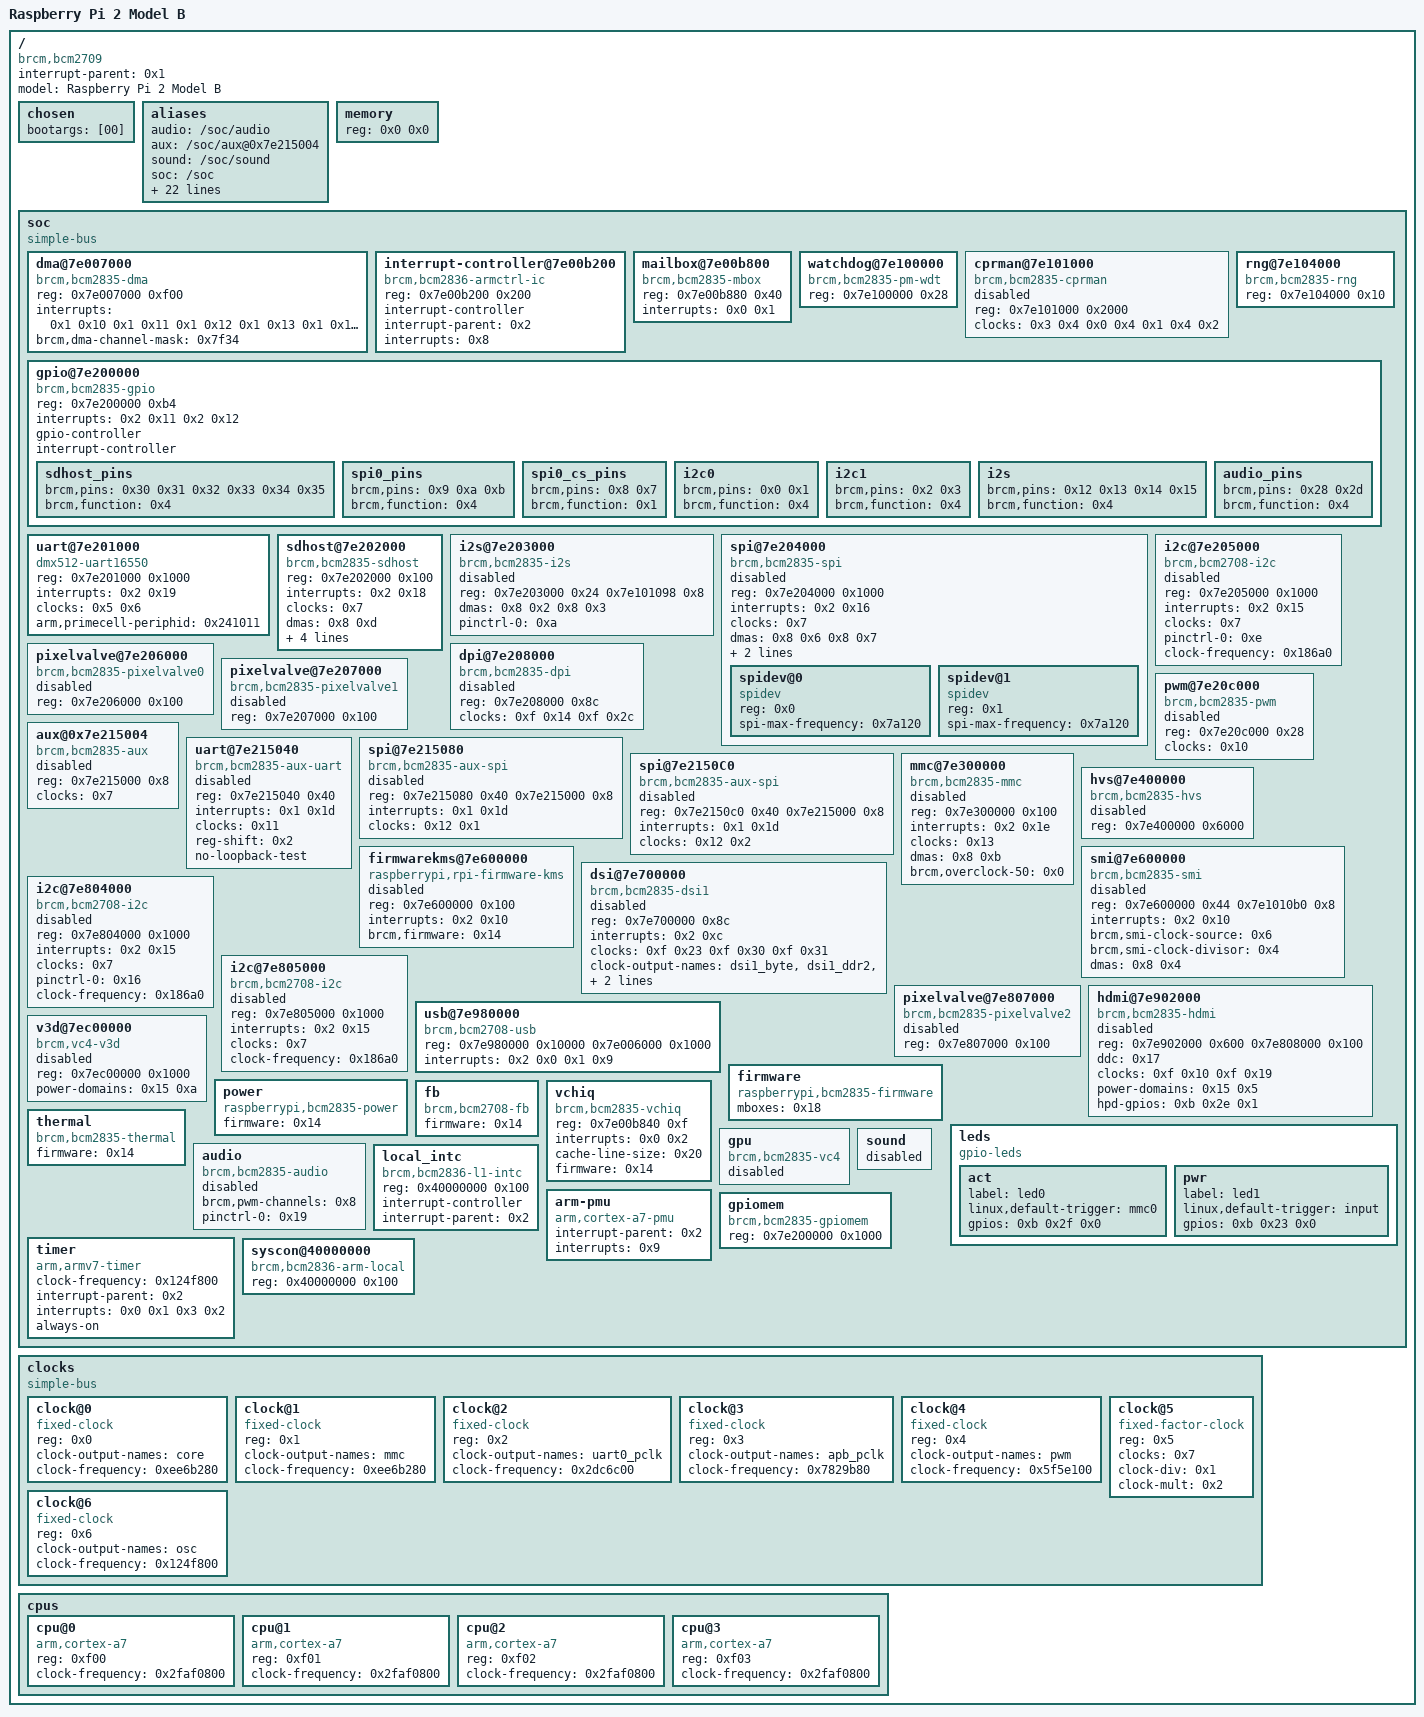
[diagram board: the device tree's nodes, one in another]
/dts-v1/;

/ {
	#address-cells = <0x1>;
	#size-cells = <0x1>;
	interrupt-parent = <0x1>;
	compatible = "brcm,bcm2709";
	model = "Raspberry Pi 2 Model B";

	chosen {
		bootargs = [00];
	};

	aliases {
		audio = "/soc/audio";
		aux = "/soc/aux@0x7e215004";
		sound = "/soc/sound";
		soc = "/soc";
		dma = "/soc/dma@7e007000";
		intc = "/soc/interrupt-controller@7e00b200";
		watchdog = "/soc/watchdog@7e100000";
		random = "/soc/rng@7e104000";
		mailbox = "/soc/mailbox@7e00b800";
		gpio = "/soc/gpio@7e200000";
		/*uart0 = "/soc/uart@7e201000"; */
		sdhost = "/soc/sdhost@7e202000";
		i2s = "/soc/i2s@7e203000";
		spi0 = "/soc/spi@7e204000";
		i2c0 = "/soc/i2c@7e205000";
		uart1 = "/soc/uart@7e215040";
		spi1 = "/soc/spi@7e215080";
		spi2 = "/soc/spi@7e2150C0";
		mmc = "/soc/mmc@7e300000";
		i2c1 = "/soc/i2c@7e804000";
		i2c2 = "/soc/i2c@7e805000";
		usb = "/soc/usb@7e980000";
		leds = "/soc/leds";
		fb = "/soc/fb";
		vchiq = "/soc/vchiq";
		thermal = "/soc/thermal";
		clocks = "/clocks";
	};

	memory {
		device_type = "memory";
		reg = <0x0 0x0>;
	};

	soc {
		compatible = "simple-bus";
		#address-cells = <0x1>;
		#size-cells = <0x1>;
		ranges = <0x7e000000 0x3f000000 0x1000000 0x40000000 0x40000000 0x40000>;
		phandle = <0x2b>;

		dma@7e007000 {
			compatible = "brcm,bcm2835-dma";
			reg = <0x7e007000 0xf00>;
			interrupts = <0x1 0x10 0x1 0x11 0x1 0x12 0x1 0x13 0x1 0x14 0x1 0x15 0x1 0x16 0x1 0x17 0x1 0x18 0x1 0x19 0x1 0x1a 0x1 0x1b 0x1 0x1b 0x1 0x1b 0x1 0x1b 0x1 0x1c>;
			interrupt-names = "dma0", "dma1", "dma2", "dma3", "dma4", "dma5", "dma6", "dma7", "dma8", "dma9", "dma10", "dma11", "dma12", "dma13", "dma14", "dma-shared-all";
			#dma-cells = <0x1>;
			brcm,dma-channel-mask = <0x7f34>;
			phandle = <0x8>;
		};

		interrupt-controller@7e00b200 {
			compatible = "brcm,bcm2836-armctrl-ic";
			reg = <0x7e00b200 0x200>;
			interrupt-controller;
			#interrupt-cells = <0x2>;
			interrupt-parent = <0x2>;
			interrupts = <0x8>;
			phandle = <0x1>;
		};

		mailbox@7e00b800 {
			compatible = "brcm,bcm2835-mbox";
			reg = <0x7e00b880 0x40>;
			interrupts = <0x0 0x1>;
			#mbox-cells = <0x0>;
			phandle = <0x18>;
		};

		watchdog@7e100000 {
			compatible = "brcm,bcm2835-pm-wdt";
			reg = <0x7e100000 0x28>;
			status = "okay";
			phandle = <0x28>;
		};

		cprman@7e101000 {
			compatible = "brcm,bcm2835-cprman";
			#clock-cells = <0x1>;
			reg = <0x7e101000 0x2000>;
			clocks = <0x3 0x4 0x0 0x4 0x1 0x4 0x2>;
			status = "disabled";
			phandle = <0xf>;
		};

		rng@7e104000 {
			compatible = "brcm,bcm2835-rng";
			reg = <0x7e104000 0x10>;
			status = "okay";
			phandle = <0x29>;
		};

		gpio@7e200000 {
			compatible = "brcm,bcm2835-gpio";
			reg = <0x7e200000 0xb4>;
			interrupts = <0x2 0x11 0x2 0x12>;
			gpio-controller;
			#gpio-cells = <0x2>;
			interrupt-controller;
			#interrupt-cells = <0x2>;
			phandle = <0xb>;

			sdhost_pins {
				brcm,pins = <0x30 0x31 0x32 0x33 0x34 0x35>;
				brcm,function = <0x4>;
				phandle = <0x9>;
			};

			spi0_pins {
				brcm,pins = <0x9 0xa 0xb>;
				brcm,function = <0x4>;
				phandle = <0xc>;
			};

			spi0_cs_pins {
				brcm,pins = <0x8 0x7>;
				brcm,function = <0x1>;
				phandle = <0xd>;
			};

			i2c0 {
				brcm,pins = <0x0 0x1>;
				brcm,function = <0x4>;
				phandle = <0xe>;
			};

			i2c1 {
				brcm,pins = <0x2 0x3>;
				brcm,function = <0x4>;
				phandle = <0x16>;
			};

			i2s {
				brcm,pins = <0x12 0x13 0x14 0x15>;
				brcm,function = <0x4>;
				phandle = <0xa>;
			};

			audio_pins {
				brcm,pins = <0x28 0x2d>;
				brcm,function = <0x4>;
				phandle = <0x19>;
			};
		};

		uart@7e201000 {
			compatible = "dmx512-uart16550";
			reg = <0x7e201000 0x1000>;
			interrupts = <0x2 0x19>;
			clocks = <0x5 0x6>;
			clock-names = "uartclk", "apb_pclk";
			arm,primecell-periphid = <0x241011>;
			status = "okay";
			phandle = <0x1f>;
		};
/*
		uart@7e201000 {
			compatible = "arm,pl011", "arm,primecell";
			reg = <0x7e201000 0x1000>;
			interrupts = <0x2 0x19>;
			clocks = <0x5 0x6>;
			clock-names = "uartclk", "apb_pclk";
			arm,primecell-periphid = <0x241011>;
			status = "okay";
			phandle = <0x1f>;
		};
*/

		sdhost@7e202000 {
			compatible = "brcm,bcm2835-sdhost";
			reg = <0x7e202000 0x100>;
			interrupts = <0x2 0x18>;
			clocks = <0x7>;
			dmas = <0x8 0xd>;
			dma-names = "rx-tx";
			brcm,overclock-50 = <0x0>;
			brcm,pio-limit = <0x1>;
			status = "okay";
			pinctrl-names = "default";
			pinctrl-0 = <0x9>;
			bus-width = <0x4>;
			phandle = <0x2a>;
		};

		i2s@7e203000 {
			compatible = "brcm,bcm2835-i2s";
			#sound-dai-cells = <0x0>;
			reg = <0x7e203000 0x24 0x7e101098 0x8>;
			dmas = <0x8 0x2 0x8 0x3>;
			dma-names = "tx", "rx";
			status = "disabled";
			pinctrl-names = "default";
			pinctrl-0 = <0xa>;
			phandle = <0x21>;
		};

		spi@7e204000 {
			compatible = "brcm,bcm2835-spi";
			reg = <0x7e204000 0x1000>;
			interrupts = <0x2 0x16>;
			clocks = <0x7>;
			#address-cells = <0x1>;
			#size-cells = <0x0>;
			status = "disabled";
			dmas = <0x8 0x6 0x8 0x7>;
			dma-names = "tx", "rx";
			cs-gpios = <0xb 0x8 0x1 0xb 0x7 0x1>;
			pinctrl-names = "default";
			pinctrl-0 = <0xc 0xd>;
			phandle = <0x22>;

			spidev@0 {
				compatible = "spidev";
				reg = <0x0>;
				#address-cells = <0x1>;
				#size-cells = <0x0>;
				spi-max-frequency = <0x7a120>;
				phandle = <0x2c>;
			};

			spidev@1 {
				compatible = "spidev";
				reg = <0x1>;
				#address-cells = <0x1>;
				#size-cells = <0x0>;
				spi-max-frequency = <0x7a120>;
				phandle = <0x2d>;
			};
		};

		i2c@7e205000 {
			compatible = "brcm,bcm2708-i2c";
			reg = <0x7e205000 0x1000>;
			interrupts = <0x2 0x15>;
			clocks = <0x7>;
			#address-cells = <0x1>;
			#size-cells = <0x0>;
			status = "disabled";
			pinctrl-names = "default";
			pinctrl-0 = <0xe>;
			clock-frequency = <0x186a0>;
			phandle = <0x23>;
		};

		pixelvalve@7e206000 {
			compatible = "brcm,bcm2835-pixelvalve0";
			reg = <0x7e206000 0x100>;
			status = "disabled";
			phandle = <0x2e>;
		};

		dpi@7e208000 {
			compatible = "brcm,bcm2835-dpi";
			reg = <0x7e208000 0x8c>;
			clocks = <0xf 0x14 0xf 0x2c>;
			clock-names = "core", "pixel";
			#address-cells = <0x1>;
			#size-cells = <0x0>;
			status = "disabled";
			phandle = <0x2f>;
		};

		pixelvalve@7e207000 {
			compatible = "brcm,bcm2835-pixelvalve1";
			reg = <0x7e207000 0x100>;
			status = "disabled";
			phandle = <0x30>;
		};

		pwm@7e20c000 {
			compatible = "brcm,bcm2835-pwm";
			reg = <0x7e20c000 0x28>;
			clocks = <0x10>;
			#pwm-cells = <0x2>;
			status = "disabled";
			phandle = <0x31>;
		};

		aux@0x7e215004 {
			compatible = "brcm,bcm2835-aux";
			#clock-cells = <0x1>;
			reg = <0x7e215000 0x8>;
			clocks = <0x7>;
			status = "disabled";
			phandle = <0x12>;
		};

		uart@7e215040 {
			compatible = "brcm,bcm2835-aux-uart", "ns16550";
			reg = <0x7e215040 0x40>;
			interrupts = <0x1 0x1d>;
			clocks = <0x11>;
			reg-shift = <0x2>;
			no-loopback-test;
			status = "disabled";
			phandle = <0x20>;
		};

		spi@7e215080 {
			compatible = "brcm,bcm2835-aux-spi";
			reg = <0x7e215080 0x40 0x7e215000 0x8>;
			interrupts = <0x1 0x1d>;
			clocks = <0x12 0x1>;
			#address-cells = <0x1>;
			#size-cells = <0x0>;
			status = "disabled";
			phandle = <0x32>;
		};

		spi@7e2150C0 {
			compatible = "brcm,bcm2835-aux-spi";
			reg = <0x7e2150c0 0x40 0x7e215000 0x8>;
			interrupts = <0x1 0x1d>;
			clocks = <0x12 0x2>;
			#address-cells = <0x1>;
			#size-cells = <0x0>;
			status = "disabled";
			phandle = <0x33>;
		};

		mmc@7e300000 {
			compatible = "brcm,bcm2835-mmc";
			reg = <0x7e300000 0x100>;
			interrupts = <0x2 0x1e>;
			clocks = <0x13>;
			dmas = <0x8 0xb>;
			dma-names = "rx-tx";
			brcm,overclock-50 = <0x0>;
			status = "disabled";
			phandle = <0x34>;
		};

		hvs@7e400000 {
			compatible = "brcm,bcm2835-hvs";
			reg = <0x7e400000 0x6000>;
			status = "disabled";
			phandle = <0x35>;
		};

		firmwarekms@7e600000 {
			compatible = "raspberrypi,rpi-firmware-kms";
			reg = <0x7e600000 0x100>;
			interrupts = <0x2 0x10>;
			brcm,firmware = <0x14>;
			status = "disabled";
			phandle = <0x36>;
		};

		smi@7e600000 {
			compatible = "brcm,bcm2835-smi";
			reg = <0x7e600000 0x44 0x7e1010b0 0x8>;
			interrupts = <0x2 0x10>;
			brcm,smi-clock-source = <0x6>;
			brcm,smi-clock-divisor = <0x4>;
			dmas = <0x8 0x4>;
			dma-names = "rx-tx";
			status = "disabled";
			phandle = <0x37>;
		};

		dsi@7e700000 {
			#address-cells = <0x1>;
			#size-cells = <0x0>;
			#clock-cells = <0x1>;
			compatible = "brcm,bcm2835-dsi1";
			reg = <0x7e700000 0x8c>;
			interrupts = <0x2 0xc>;
			clocks = <0xf 0x23 0xf 0x30 0xf 0x31>;
			clock-names = "phy", "escape", "pixel";
			clock-output-names = "dsi1_byte", "dsi1_ddr2", "dsi1_ddr";
			status = "disabled";
			power-domains = <0x15 0x12>;
			phandle = <0x4>;
		};

		i2c@7e804000 {
			compatible = "brcm,bcm2708-i2c";
			reg = <0x7e804000 0x1000>;
			interrupts = <0x2 0x15>;
			clocks = <0x7>;
			#address-cells = <0x1>;
			#size-cells = <0x0>;
			status = "disabled";
			pinctrl-names = "default";
			pinctrl-0 = <0x16>;
			clock-frequency = <0x186a0>;
			phandle = <0x24>;
		};

		i2c@7e805000 {
			compatible = "brcm,bcm2708-i2c";
			reg = <0x7e805000 0x1000>;
			interrupts = <0x2 0x15>;
			clocks = <0x7>;
			#address-cells = <0x1>;
			#size-cells = <0x0>;
			status = "disabled";
			clock-frequency = <0x186a0>;
			phandle = <0x17>;
		};

		pixelvalve@7e807000 {
			compatible = "brcm,bcm2835-pixelvalve2";
			reg = <0x7e807000 0x100>;
			status = "disabled";
			phandle = <0x38>;
		};

		hdmi@7e902000 {
			compatible = "brcm,bcm2835-hdmi";
			reg = <0x7e902000 0x600 0x7e808000 0x100>;
			ddc = <0x17>;
			clocks = <0xf 0x10 0xf 0x19>;
			clock-names = "pixel", "hdmi";
			power-domains = <0x15 0x5>;
			status = "disabled";
			hpd-gpios = <0xb 0x2e 0x1>;
			phandle = <0x39>;
		};

		usb@7e980000 {
			compatible = "brcm,bcm2708-usb";
			reg = <0x7e980000 0x10000 0x7e006000 0x1000>;
			interrupts = <0x2 0x0 0x1 0x9>;
			phandle = <0x3a>;
		};

		v3d@7ec00000 {
			compatible = "brcm,vc4-v3d";
			reg = <0x7ec00000 0x1000>;
			power-domains = <0x15 0xa>;
			status = "disabled";
			phandle = <0x3b>;
		};

		firmware {
			compatible = "raspberrypi,bcm2835-firmware";
			mboxes = <0x18>;
			phandle = <0x14>;
		};

		power {
			compatible = "raspberrypi,bcm2835-power";
			firmware = <0x14>;
			#power-domain-cells = <0x1>;
			phandle = <0x15>;
		};

		leds {
			compatible = "gpio-leds";
			phandle = <0x3c>;

			act {
				label = "led0";
				linux,default-trigger = "mmc0";
				gpios = <0xb 0x2f 0x0>;
				phandle = <0x25>;
			};

			pwr {
				label = "led1";
				linux,default-trigger = "input";
				gpios = <0xb 0x23 0x0>;
				phandle = <0x26>;
			};
		};

		fb {
			compatible = "brcm,bcm2708-fb";
			firmware = <0x14>;
			status = "okay";
			phandle = <0x3d>;
		};

		vchiq {
			compatible = "brcm,bcm2835-vchiq";
			reg = <0x7e00b840 0xf>;
			interrupts = <0x0 0x2>;
			cache-line-size = <0x20>;
			firmware = <0x14>;
			phandle = <0x1a>;
		};

		thermal {
			compatible = "brcm,bcm2835-thermal";
			firmware = <0x14>;
			phandle = <0x3e>;
		};

		gpu {
			compatible = "brcm,bcm2835-vc4";
			status = "disabled";
			phandle = <0x3f>;
		};

		audio {
			compatible = "brcm,bcm2835-audio";
			brcm,pwm-channels = <0x8>;
			status = "disabled";
			pinctrl-names = "default";
			pinctrl-0 = <0x19>;
			phandle = <0x27>;
		};

		sound {
			status = "disabled";
			phandle = <0x40>;
		};

		local_intc {
			compatible = "brcm,bcm2836-l1-intc";
			reg = <0x40000000 0x100>;
			interrupt-controller;
			#interrupt-cells = <0x1>;
			interrupt-parent = <0x2>;
			phandle = <0x2>;
		};

		arm-pmu {
			compatible = "arm,cortex-a7-pmu";
			interrupt-parent = <0x2>;
			interrupts = <0x9>;
		};

		gpiomem {
			compatible = "brcm,bcm2835-gpiomem";
			reg = <0x7e200000 0x1000>;
			status = "okay";
		};

		timer {
			compatible = "arm,armv7-timer";
			clock-frequency = <0x124f800>;
			interrupt-parent = <0x2>;
			interrupts = <0x0 0x1 0x3 0x2>;
			always-on;
		};

		syscon@40000000 {
			compatible = "brcm,bcm2836-arm-local", "syscon";
			reg = <0x40000000 0x100>;
		};
	};

	clocks {
		compatible = "simple-bus";
		#address-cells = <0x1>;
		#size-cells = <0x0>;
		phandle = <0x41>;

		clock@0 {
			compatible = "fixed-clock";
			reg = <0x0>;
			#clock-cells = <0x0>;
			clock-output-names = "core";
			clock-frequency = <0xee6b280>;
			phandle = <0x7>;
		};

		clock@1 {
			compatible = "fixed-clock";
			reg = <0x1>;
			#clock-cells = <0x0>;
			clock-output-names = "mmc";
			clock-frequency = <0xee6b280>;
			phandle = <0x13>;
		};

		clock@2 {
			compatible = "fixed-clock";
			reg = <0x2>;
			#clock-cells = <0x0>;
			clock-output-names = "uart0_pclk";
			clock-frequency = <0x2dc6c00>;
			phandle = <0x5>;
		};

		clock@3 {
			compatible = "fixed-clock";
			reg = <0x3>;
			#clock-cells = <0x0>;
			clock-output-names = "apb_pclk";
			clock-frequency = <0x7829b80>;
			phandle = <0x6>;
		};

		clock@4 {
			compatible = "fixed-clock";
			reg = <0x4>;
			#clock-cells = <0x0>;
			clock-output-names = "pwm";
			clock-frequency = <0x5f5e100>;
			phandle = <0x10>;
		};

		clock@5 {
			compatible = "fixed-factor-clock";
			reg = <0x5>;
			clocks = <0x7>;
			#clock-cells = <0x0>;
			clock-div = <0x1>;
			clock-mult = <0x2>;
			phandle = <0x11>;
		};

		clock@6 {
			compatible = "fixed-clock";
			reg = <0x6>;
			#clock-cells = <0x0>;
			clock-output-names = "osc";
			clock-frequency = <0x124f800>;
			phandle = <0x3>;
		};
	};

	__overrides__ {
		cache_line_size = [00 00 00 1a 63 61 63 68 65 2d 6c 69 6e 65 2d 73 69 7a 65 3a 30 00];
		arm_freq = <0x1b 0x636c6f63 0x6b2d6672 0x65717565 0x6e63793a 0x30000000 0x1c636c 0x6f636b2d 0x66726571 0x75656e63 0x793a3000 0x1d 0x636c6f63 0x6b2d6672 0x65717565 0x6e63793a 0x30000000 0x1e636c 0x6f636b2d 0x66726571 0x75656e63 0x793a3000>;
		uart0 = [00 00 00 1f 73 74 61 74 75 73 00];
		uart0_clkrate = [00 00 00 05 63 6c 6f 63 6b 2d 66 72 65 71 75 65 6e 63 79 3a 30 00];
		uart1 = "", "", "", " status";
		i2s = "", "", "", "!status";
		spi = "", "", "", "\"status";
		i2c0 = "", "", "", "#status";
		i2c1 = "", "", "", "$status";
		i2c2_iknowwhatimdoing = [00 00 00 17 73 74 61 74 75 73 00];
		i2c0_baudrate = "", "", "", "#clock-frequency:0";
		i2c1_baudrate = "", "", "", "$clock-frequency:0";
		i2c2_baudrate = [00 00 00 17 63 6c 6f 63 6b 2d 66 72 65 71 75 65 6e 63 79 3a 30 00];
		core_freq = "", "", "", "\aclock-frequency:0";
		act_led_gpio = "", "", "", "%gpios:4";
		act_led_activelow = "", "", "", "%gpios:8";
		act_led_trigger = "", "", "", "%linux,default-trigger";
		pwr_led_gpio = "", "", "", "&gpios:4";
		pwr_led_activelow = "", "", "", "&gpios:8";
		pwr_led_trigger = "", "", "", "&linux,default-trigger";
		audio = "", "", "", "'status";
		watchdog = "", "", "", "(status";
		random = "", "", "", ")status";
		sd_overclock = "", "", "", "*brcm,overclock-50:0";
		sd_force_pio = "", "", "", "*brcm,force-pio?";
		sd_pio_limit = "", "", "", "*brcm,pio-limit:0";
		sd_debug = "", "", "", "*brcm,debug";
	};

	cpus {
		#address-cells = <0x1>;
		#size-cells = <0x0>;
		phandle = <0x42>;

		cpu@0 {
			device_type = "cpu";
			compatible = "arm,cortex-a7";
			reg = <0xf00>;
			clock-frequency = <0x2faf0800>;
			phandle = <0x1b>;
		};

		cpu@1 {
			device_type = "cpu";
			compatible = "arm,cortex-a7";
			reg = <0xf01>;
			clock-frequency = <0x2faf0800>;
			phandle = <0x1c>;
		};

		cpu@2 {
			device_type = "cpu";
			compatible = "arm,cortex-a7";
			reg = <0xf02>;
			clock-frequency = <0x2faf0800>;
			phandle = <0x1d>;
		};

		cpu@3 {
			device_type = "cpu";
			compatible = "arm,cortex-a7";
			reg = <0xf03>;
			clock-frequency = <0x2faf0800>;
			phandle = <0x1e>;
		};
	};

	__symbols__ {
		soc = "/soc";
		dma = "/soc/dma@7e007000";
		intc = "/soc/interrupt-controller@7e00b200";
		mailbox = "/soc/mailbox@7e00b800";
		watchdog = "/soc/watchdog@7e100000";
		cprman = "/soc/cprman@7e101000";
		random = "/soc/rng@7e104000";
		gpio = "/soc/gpio@7e200000";
		sdhost_pins = "/soc/gpio@7e200000/sdhost_pins";
		spi0_pins = "/soc/gpio@7e200000/spi0_pins";
		spi0_cs_pins = "/soc/gpio@7e200000/spi0_cs_pins";
		i2c0_pins = "/soc/gpio@7e200000/i2c0";
		i2c1_pins = "/soc/gpio@7e200000/i2c1";
		i2s_pins = "/soc/gpio@7e200000/i2s";
		audio_pins = "/soc/gpio@7e200000/audio_pins";
		uart0 = "/soc/uart@7e201000";
		sdhost = "/soc/sdhost@7e202000";
		i2s = "/soc/i2s@7e203000";
		spi0 = "/soc/spi@7e204000";
		spidev0 = "/soc/spi@7e204000/spidev@0";
		spidev1 = "/soc/spi@7e204000/spidev@1";
		i2c0 = "/soc/i2c@7e205000";
		pixelvalve0 = "/soc/pixelvalve@7e206000";
		dpi = "/soc/dpi@7e208000";
		pixelvalve1 = "/soc/pixelvalve@7e207000";
		pwm = "/soc/pwm@7e20c000";
		aux = "/soc/aux@0x7e215004";
		uart1 = "/soc/uart@7e215040";
		spi1 = "/soc/spi@7e215080";
		spi2 = "/soc/spi@7e2150C0";
		mmc = "/soc/mmc@7e300000";
		hvs = "/soc/hvs@7e400000";
		firmwarekms = "/soc/firmwarekms@7e600000";
		smi = "/soc/smi@7e600000";
		dsi1 = "/soc/dsi@7e700000";
		i2c1 = "/soc/i2c@7e804000";
		i2c2 = "/soc/i2c@7e805000";
		pixelvalve2 = "/soc/pixelvalve@7e807000";
		hdmi = "/soc/hdmi@7e902000";
		usb = "/soc/usb@7e980000";
		v3d = "/soc/v3d@7ec00000";
		firmware = "/soc/firmware";
		power = "/soc/power";
		leds = "/soc/leds";
		act_led = "/soc/leds/act";
		pwr_led = "/soc/leds/pwr";
		fb = "/soc/fb";
		vchiq = "/soc/vchiq";
		thermal = "/soc/thermal";
		gpu = "/soc/gpu";
		audio = "/soc/audio";
		sound = "/soc/sound";
		local_intc = "/soc/local_intc";
		clocks = "/clocks";
		clk_core = "/clocks/clock@0";
		clk_mmc = "/clocks/clock@1";
		clk_uart0 = "/clocks/clock@2";
		clk_apb_p = "/clocks/clock@3";
		clk_pwm = "/clocks/clock@4";
		clk_uart1 = "/clocks/clock@5";
		clk_osc = "/clocks/clock@6";
		cpus = "/cpus";
		v7_cpu0 = "/cpus/cpu@0";
		v7_cpu1 = "/cpus/cpu@1";
		v7_cpu2 = "/cpus/cpu@2";
		v7_cpu3 = "/cpus/cpu@3";
	};
};
